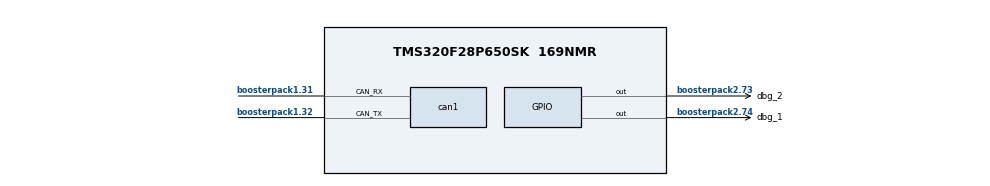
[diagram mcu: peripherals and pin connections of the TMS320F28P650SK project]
/**
 * AI AGENTS: Do not edit this file directly. There is no validation or error feedback when
 * editing manually — mistakes will be silent until the file is loaded in SysConfig.
 * Use the SysConfig MCP server instead to make changes with immediate error reporting.
 *
 * These arguments were used when this file was generated. They will be automatically applied on subsequent loads
 * via the GUI or CLI. Run CLI with '--help' for additional information on how to override these arguments.
 * @cliArgs --board "/boards/LAUNCHXL_F28P65X" --device "F28P65x" --part "F28P65x_169NMR" --package "169NMR" --context "CPU1" --product "C2000WARE@26.01.00.00"
 * @v2CliArgs --board "/boards/LAUNCHXL_F28P65X" --device "TMS320F28P650SK" --package "169NMR" --variant "TMS320F28P650SK6" --context "CPU1" --product "C2000WARE@26.01.00.00"
 * @versions {"tool":"1.28.0+4696"}
 */

/**
 * Import the modules used in this configuration.
 */
const led            = scripting.addModule("/driverlib/board_components/led", {}, false);
const led1           = led.addInstance();
const led2           = led.addInstance();
const can            = scripting.addModule("/driverlib/can.js", {}, false);
const can1           = can.addInstance();
const cputimer       = scripting.addModule("/driverlib/cputimer.js", {}, false);
const cputimer1      = cputimer.addInstance();
const device_support = scripting.addModule("/driverlib/device_support.js");
const gpio           = scripting.addModule("/driverlib/gpio.js", {}, false);
const gpio1          = gpio.addInstance();
const gpio2          = gpio.addInstance();
const gpio3          = gpio.addInstance();
const sci            = scripting.addModule("/driverlib/sci.js", {}, false);
const sci1           = sci.addInstance();

/**
 * Write custom configuration values to the imported modules.
 */
led1.$hardware              = system.deviceData.board.components.LED4;
led1.$name                  = "DEVICE_LED1";
led1.gpio.writeInitialValue = true;

led2.$name                  = "DEVICE_LED2";
led2.$hardware              = system.deviceData.board.components.LED5;
led2.gpio.writeInitialValue = true;

can1.$name                   = "myCAN0";
can1.bitRate                 = "250000";
can1.enableInterrupt         = true;
can1.registerInterrupts      = true;
can1.interruptFlags          = ["CAN_INT_ERROR","CAN_INT_IE0","CAN_INT_STATUS"];
can1.interruptLine           = ["CAN_GLOBAL_INT_CANINT0"];
can1.$hardware               = system.deviceData.board.components.BP_SITE_1.subComponents.CAN;
can1.msgObjsUsed             = [1,2,31,32];
can1.msgObj1.$name           = "msgObj0";
can1.msgObj1.msgID           = 4;
can1.msgObj1.flags           = ["CAN_MSG_OBJ_RX_INT_ENABLE"];
can1.msgObj2.$name           = "msgObj1";
can1.msgObj2.msgID           = 5;
can1.msgObj2.msgType         = "CAN_MSG_OBJ_TYPE_TX";
can1.msgObj2.flags           = ["CAN_MSG_OBJ_TX_INT_ENABLE"];
can1.msgObj2.msgLen          = 8;
can1.can0Int.enableInterrupt = true;
can1.can.$assign             = "CANA";
can1.can.can_rxPin.$assign   = "boosterpack1.31";
can1.can.can_txPin.$assign   = "boosterpack1.32";
can1.msgObj31.$name          = "msgObj2";
can1.msgObj31.msgType        = "CAN_MSG_OBJ_TYPE_RXTX_REMOTE";
can1.msgObj31.msgLen         = 4;
can1.msgObj31.msgID          = 100;
can1.msgObj32.$name          = "msgObj3";
can1.msgObj32.msgID          = 101;
can1.msgObj32.msgType        = "CAN_MSG_OBJ_TYPE_RXTX_REMOTE";
can1.msgObj32.msgLen         = 6;

cputimer1.cputimerBase             = "CPUTIMER2_BASE";
cputimer1.$name                    = "myCPUTIMER2";
cputimer1.timerPeriod              = 199999;
cputimer1.enableInterrupt          = true;
cputimer1.registerInterrupts       = true;
cputimer1.timerInt.enableInterrupt = true;

gpio1.$name             = "dbg_1";
gpio1.direction         = "GPIO_DIR_MODE_OUT";
gpio1.writeInitialValue = true;
gpio1.gpioPin.$assign   = "boosterpack2.74";

gpio2.$name             = "dbg_2";
gpio2.direction         = "GPIO_DIR_MODE_OUT";
gpio2.writeInitialValue = true;
gpio2.gpioPin.$assign   = "boosterpack2.73";

gpio3.$name             = "dbg_3";
gpio3.direction         = "GPIO_DIR_MODE_OUT";
gpio3.writeInitialValue = true;

sci1.$name        = "mySCIA";
sci1.$hardware    = system.deviceData.board.components.XDS_UART.subComponents.XDS_SCI_INST1;
sci1.rxQual.$name = "myGPIOQUAL0";
sci1.txQual.$name = "myGPIOQUAL1";

/**
 * Pinmux solution for unlocked pins/peripherals. This ensures that minor changes to the automatic solver in a future
 * version of the tool will not impact the pinmux you originally saw.  These lines can be completely deleted in order to
 * re-solve from scratch.
 */
led1.gpio.gpioPin.$suggestSolution  = "boosterpack1.13";
led2.gpio.gpioPin.$suggestSolution  = "boosterpack2.53";
gpio3.gpioPin.$suggestSolution      = "boosterpack2.51";
sci1.sci.$suggestSolution           = "SCIA";
sci1.sci.sci_rxPin.$suggestSolution = "boosterpack1.3";
sci1.sci.sci_txPin.$suggestSolution = "boosterpack1.4";
